VERSION ""

NS_ :

BS_:

BU_: CAN_exp6

BO_ 257 Front_Door_Status: 8 CAN_exp6
 SG_ Front_Right_Door_Status : 8|8@1+ (1,0) [0|255] "" Vector__XXX
 SG_ Front_Left_Door_Status : 0|8@1+ (1,0) [0|255] "" Vector__XXX

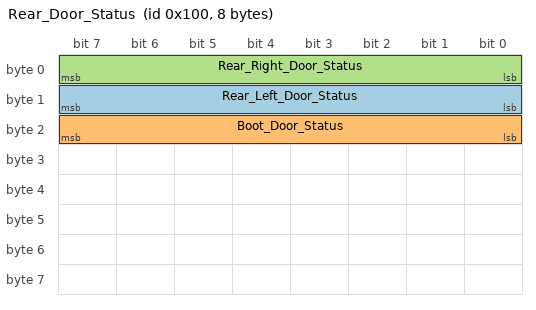
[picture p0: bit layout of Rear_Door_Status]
BO_ 256 Rear_Door_Status: 8 CAN_exp6
 SG_ Rear_Left_Door_Status : 8|8@1+ (1,0) [0|255] "" Vector__XXX
 SG_ Boot_Door_Status : 16|8@1+ (1,0) [0|255] "" Vector__XXX
 SG_ Rear_Right_Door_Status : 0|8@1+ (1,0) [0|255] "" Vector__XXX
